# AST1080 register map
File version: 1.0
CPU: CM4 r0p1, little endian, MPU, FPU, 4 interrupt priority bits, 256 interrupts
Registers are 32-bit, read-write, reset 0x0 unless marked. A register's access mark holds for its fields unless they carry their own. Offsets are from the block's base; [hi:lo] are bit positions; {n}, {i} and the like mark numbered series.

## pric_io (part 2 of 3)
Base 0x74100000
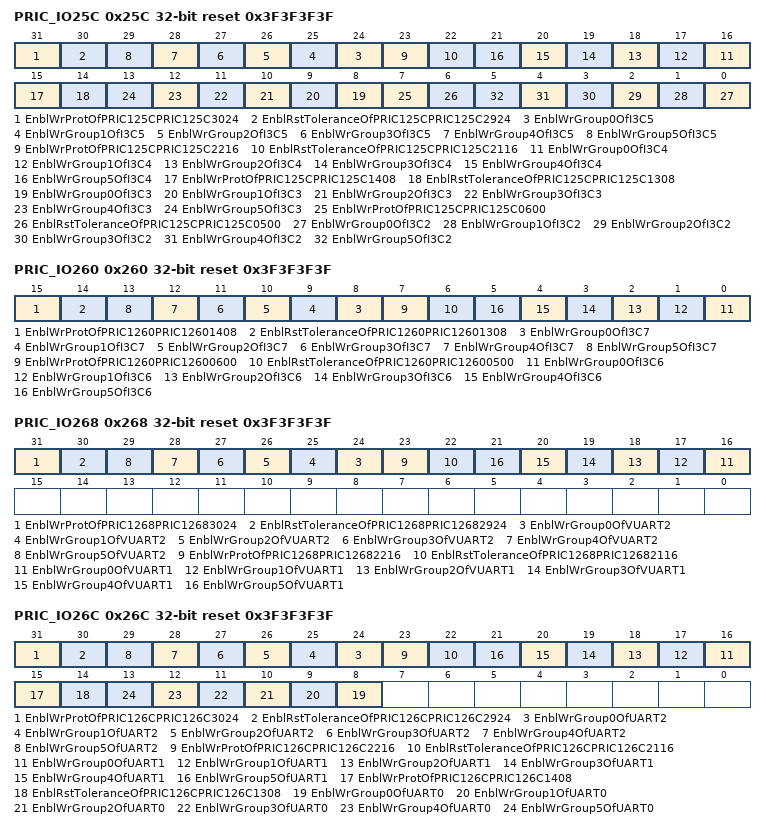
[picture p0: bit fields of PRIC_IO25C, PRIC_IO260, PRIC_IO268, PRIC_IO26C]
0x25C PRIC_IO25C reset 0x3F3F3F3F — Slave Write Group Setting Register \#23
  [31] EnblWrProtOfPRIC125CPRIC125C3024 — Enable Write Protection of PRIC125CPRIC1_25C[30:24]
  [30] EnblRstToleranceOfPRIC125CPRIC125C2924 — Enable Reset Tolerance of PRIC125CPRIC1_25C[29:24]
    0=Reset_By_SRST; 1=Reset_By_SRST_And_PSP_Reset
  [n+24] EnblWrGroup{n}OfI3C5 (n=0..5) — Enable Write Group #{n} of I3C5
  [23] EnblWrProtOfPRIC125CPRIC125C2216 — Enable Write Protection of PRIC125CPRIC1_25C[22:16]
  [22] EnblRstToleranceOfPRIC125CPRIC125C2116 — Enable Reset Tolerance of PRIC125CPRIC1_25C[21:16]
    0=Reset_By_SRST; 1=Reset_By_SRST_And_PSP_Reset
  [n+16] EnblWrGroup{n}OfI3C4 (n=0..5) — Enable Write Group #{n} of I3C4
  [15] EnblWrProtOfPRIC125CPRIC125C1408 — Enable Write Protection of PRIC125CPRIC1_25C[14:08]
  [14] EnblRstToleranceOfPRIC125CPRIC125C1308 — Enable Reset Tolerance of PRIC125CPRIC1_25C[13:08]
    0=Reset_By_SRST; 1=Reset_By_SRST_And_PSP_Reset
  [n+8] EnblWrGroup{n}OfI3C3 (n=0..5) — Enable Write Group #{n} of I3C3
  [7] EnblWrProtOfPRIC125CPRIC125C0600 — Enable Write Protection of PRIC125CPRIC1_25C[06:00]
  [6] EnblRstToleranceOfPRIC125CPRIC125C0500 — Enable Reset Tolerance of PRIC125CPRIC1_25C[05:00]
    0=Reset_By_SRST; 1=Reset_By_SRST_And_PSP_Reset
  [n] EnblWrGroup{n}OfI3C2 (n=0..5) — Enable Write Group #{n} of I3C2
0x260 PRIC_IO260 reset 0x3F3F3F3F — Slave Write Group Setting Register \#24
  [15] EnblWrProtOfPRIC1260PRIC12601408 — Enable Write Protection of PRIC1260PRIC1_260[14:08]
  [14] EnblRstToleranceOfPRIC1260PRIC12601308 — Enable Reset Tolerance of PRIC1260PRIC1_260[13:08]
    0=Reset_By_SRST; 1=Reset_By_SRST_And_PSP_Reset
  [n+8] EnblWrGroup{n}OfI3C7 (n=0..5) — Enable Write Group #{n} of I3C7
  [7] EnblWrProtOfPRIC1260PRIC12600600 — Enable Write Protection of PRIC1260PRIC1_260[06:00]
  [6] EnblRstToleranceOfPRIC1260PRIC12600500 — Enable Reset Tolerance of PRIC1260PRIC1_260[05:00]
    0=Reset_By_SRST; 1=Reset_By_SRST_And_PSP_Reset
  [n] EnblWrGroup{n}OfI3C6 (n=0..5) — Enable Write Group #{n} of I3C6
0x264 PRIC_IO264 reset 0x3F3F3F3F (reset mask 0x0) — Slave Write Group Setting Register \#25
0x268 PRIC_IO268 reset 0x3F3F3F3F — Slave Write Group Setting Register \#26
  [31] EnblWrProtOfPRIC1268PRIC12683024 — Enable Write Protection of PRIC1268PRIC1_268[30:24]
  [30] EnblRstToleranceOfPRIC1268PRIC12682924 — Enable Reset Tolerance of PRIC1268PRIC1_268[29:24]
    0=Reset_By_SRST; 1=Reset_By_SRST_And_PSP_Reset
  [n+24] EnblWrGroup{n}OfVUART2 (n=0..5) — Enable Write Group #{n} of VUART2
  [23] EnblWrProtOfPRIC1268PRIC12682216 — Enable Write Protection of PRIC1268PRIC1_268[22:16]
  [22] EnblRstToleranceOfPRIC1268PRIC12682116 — Enable Reset Tolerance of PRIC1268PRIC1_268[21:16]
    0=Reset_By_SRST; 1=Reset_By_SRST_And_PSP_Reset
  [n+16] EnblWrGroup{n}OfVUART1 (n=0..5) — Enable Write Group #{n} of VUART1
0x26C PRIC_IO26C reset 0x3F3F3F3F — Slave Write Group Setting Register \#27
  [31] EnblWrProtOfPRIC126CPRIC126C3024 — Enable Write Protection of PRIC126CPRIC1_26C[30:24]
  [30] EnblRstToleranceOfPRIC126CPRIC126C2924 — Enable Reset Tolerance of PRIC126CPRIC1_26C[29:24]
    0=Reset_By_SRST; 1=Reset_By_SRST_And_PSP_Reset
  [n+24] EnblWrGroup{n}OfUART2 (n=0..5) — Enable Write Group #{n} of UART2
  [23] EnblWrProtOfPRIC126CPRIC126C2216 — Enable Write Protection of PRIC126CPRIC1_26C[22:16]
  [22] EnblRstToleranceOfPRIC126CPRIC126C2116 — Enable Reset Tolerance of PRIC126CPRIC1_26C[21:16]
    0=Reset_By_SRST; 1=Reset_By_SRST_And_PSP_Reset
  [n+16] EnblWrGroup{n}OfUART1 (n=0..5) — Enable Write Group #{n} of UART1
  [15] EnblWrProtOfPRIC126CPRIC126C1408 — Enable Write Protection of PRIC126CPRIC1_26C[14:08]
  [14] EnblRstToleranceOfPRIC126CPRIC126C1308 — Enable Reset Tolerance of PRIC126CPRIC1_26C[13:08]
    0=Reset_By_SRST; 1=Reset_By_SRST_And_PSP_Reset
  [n+8] EnblWrGroup{n}OfUART0 (n=0..5) — Enable Write Group #{n} of UART0
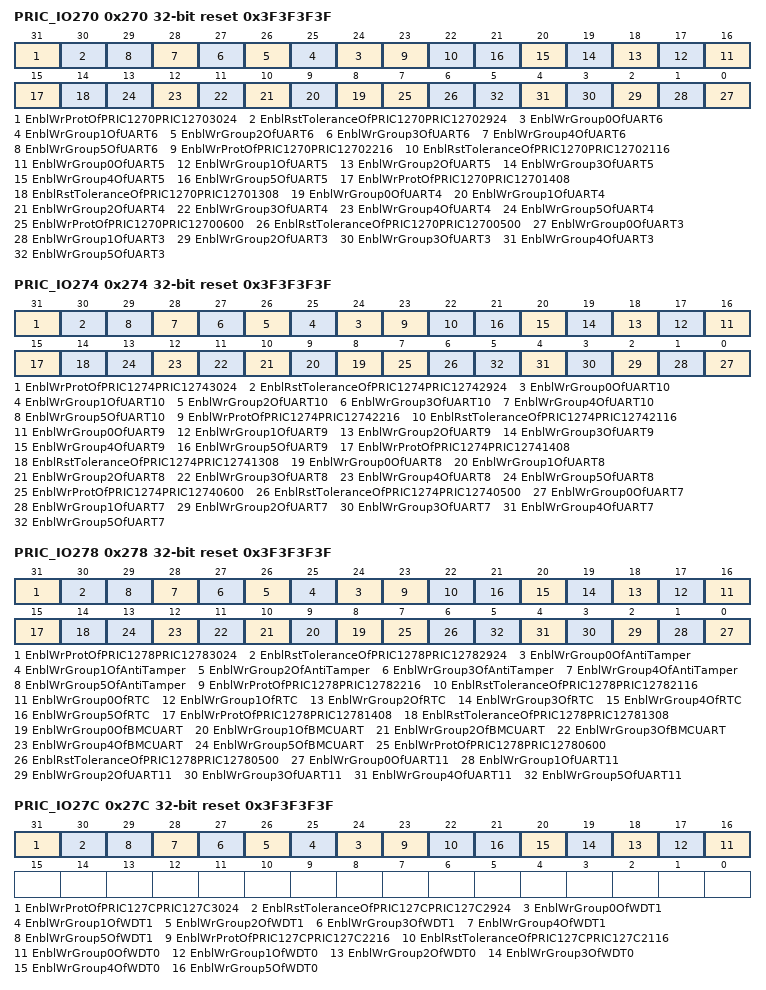
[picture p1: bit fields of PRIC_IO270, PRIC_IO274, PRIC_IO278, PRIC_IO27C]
0x270 PRIC_IO270 reset 0x3F3F3F3F — Slave Write Group Setting Register \#28
  [31] EnblWrProtOfPRIC1270PRIC12703024 — Enable Write Protection of PRIC1270PRIC1_270[30:24]
  [30] EnblRstToleranceOfPRIC1270PRIC12702924 — Enable Reset Tolerance of PRIC1270PRIC1_270[29:24]
    0=Reset_By_SRST; 1=Reset_By_SRST_And_PSP_Reset
  [n+24] EnblWrGroup{n}OfUART6 (n=0..5) — Enable Write Group #{n} of UART6
  [23] EnblWrProtOfPRIC1270PRIC12702216 — Enable Write Protection of PRIC1270PRIC1_270[22:16]
  [22] EnblRstToleranceOfPRIC1270PRIC12702116 — Enable Reset Tolerance of PRIC1270PRIC1_270[21:16]
    0=Reset_By_SRST; 1=Reset_By_SRST_And_PSP_Reset
  [n+16] EnblWrGroup{n}OfUART5 (n=0..5) — Enable Write Group #{n} of UART5
  [15] EnblWrProtOfPRIC1270PRIC12701408 — Enable Write Protection of PRIC1270PRIC1_270[14:08]
  [14] EnblRstToleranceOfPRIC1270PRIC12701308 — Enable Reset Tolerance of PRIC1270PRIC1_270[13:08]
    0=Reset_By_SRST; 1=Reset_By_SRST_And_PSP_Reset
  [n+8] EnblWrGroup{n}OfUART4 (n=0..5) — Enable Write Group #{n} of UART4
  [7] EnblWrProtOfPRIC1270PRIC12700600 — Enable Write Protection of PRIC1270PRIC1_270[06:00]
  [6] EnblRstToleranceOfPRIC1270PRIC12700500 — Enable Reset Tolerance of PRIC1270PRIC1_270[05:00]
    0=Reset_By_SRST; 1=Reset_By_SRST_And_PSP_Reset
  [n] EnblWrGroup{n}OfUART3 (n=0..5) — Enable Write Group #{n} of UART3
0x274 PRIC_IO274 reset 0x3F3F3F3F — Slave Write Group Setting Register \#29
  [31] EnblWrProtOfPRIC1274PRIC12743024 — Enable Write Protection of PRIC1274PRIC1_274[30:24]
  [30] EnblRstToleranceOfPRIC1274PRIC12742924 — Enable Reset Tolerance of PRIC1274PRIC1_274[29:24]
    0=Reset_By_SRST; 1=Reset_By_SRST_And_PSP_Reset
  [n+24] EnblWrGroup{n}OfUART10 (n=0..5) — Enable Write Group #{n} of UART10
  [23] EnblWrProtOfPRIC1274PRIC12742216 — Enable Write Protection of PRIC1274PRIC1_274[22:16]
  [22] EnblRstToleranceOfPRIC1274PRIC12742116 — Enable Reset Tolerance of PRIC1274PRIC1_274[21:16]
    0=Reset_By_SRST; 1=Reset_By_SRST_And_PSP_Reset
  [n+16] EnblWrGroup{n}OfUART9 (n=0..5) — Enable Write Group #{n} of UART9
  [15] EnblWrProtOfPRIC1274PRIC12741408 — Enable Write Protection of PRIC1274PRIC1_274[14:08]
  [14] EnblRstToleranceOfPRIC1274PRIC12741308 — Enable Reset Tolerance of PRIC1274PRIC1_274[13:08]
    0=Reset_By_SRST; 1=Reset_By_SRST_And_PSP_Reset
  [n+8] EnblWrGroup{n}OfUART8 (n=0..5) — Enable Write Group #{n} of UART8
  [7] EnblWrProtOfPRIC1274PRIC12740600 — Enable Write Protection of PRIC1274PRIC1_274[06:00]
  [6] EnblRstToleranceOfPRIC1274PRIC12740500 — Enable Reset Tolerance of PRIC1274PRIC1_274[05:00]
    0=Reset_By_SRST; 1=Reset_By_SRST_And_PSP_Reset
  [n] EnblWrGroup{n}OfUART7 (n=0..5) — Enable Write Group #{n} of UART7
0x278 PRIC_IO278 reset 0x3F3F3F3F — Slave Write Group Setting Register \#30
  [31] EnblWrProtOfPRIC1278PRIC12783024 — Enable Write Protection of PRIC1278PRIC1_278[30:24]
  [30] EnblRstToleranceOfPRIC1278PRIC12782924 — Enable Reset Tolerance of PRIC1278PRIC1_278[29:24]
    0=Reset_By_SRST; 1=Reset_By_SRST_And_PSP_Reset
  [n+24] EnblWrGroup{n}OfAntiTamper (n=0..5) — Enable Write Group #{n} of Anti Tamper
  [23] EnblWrProtOfPRIC1278PRIC12782216 — Enable Write Protection of PRIC1278PRIC1_278[22:16]
  [22] EnblRstToleranceOfPRIC1278PRIC12782116 — Enable Reset Tolerance of PRIC1278PRIC1_278[21:16]
    0=Reset_By_SRST; 1=Reset_By_SRST_And_PSP_Reset
  [n+16] EnblWrGroup{n}OfRTC (n=0..5) — Enable Write Group #{n} of RTC
  [15] EnblWrProtOfPRIC1278PRIC12781408 — Enable Write Protection of PRIC1278PRIC1_278[14:08]
  [14] EnblRstToleranceOfPRIC1278PRIC12781308 — Enable Reset Tolerance of PRIC1278PRIC1_278[13:08]
    0=Reset_By_SRST; 1=Reset_By_SRST_And_PSP_Reset
  [n+8] EnblWrGroup{n}OfBMCUART (n=0..5) — Enable Write Group #{n} of BMC UART
  [7] EnblWrProtOfPRIC1278PRIC12780600 — Enable Write Protection of PRIC1278PRIC1_278[06:00]
  [6] EnblRstToleranceOfPRIC1278PRIC12780500 — Enable Reset Tolerance of PRIC1278PRIC1_278[05:00]
    0=Reset_By_SRST; 1=Reset_By_SRST_And_PSP_Reset
  [n] EnblWrGroup{n}OfUART11 (n=0..5) — Enable Write Group #{n} of UART11
0x27C PRIC_IO27C reset 0x3F3F3F3F — Slave Write Group Setting Register \#31
  [31] EnblWrProtOfPRIC127CPRIC127C3024 — Enable Write Protection of PRIC127CPRIC1_27C[30:24]
  [30] EnblRstToleranceOfPRIC127CPRIC127C2924 — Enable Reset Tolerance of PRIC127CPRIC1_27C[29:24]
    0=Reset_By_SRST; 1=Reset_By_SRST_And_PSP_Reset
  [n+24] EnblWrGroup{n}OfWDT1 (n=0..5) — Enable Write Group #{n} of WDT 1
  [23] EnblWrProtOfPRIC127CPRIC127C2216 — Enable Write Protection of PRIC127CPRIC1_27C[22:16]
  [22] EnblRstToleranceOfPRIC127CPRIC127C2116 — Enable Reset Tolerance of PRIC127CPRIC1_27C[21:16]
    0=Reset_By_SRST; 1=Reset_By_SRST_And_PSP_Reset
  [n+16] EnblWrGroup{n}OfWDT0 (n=0..5) — Enable Write Group #{n} of WDT 0
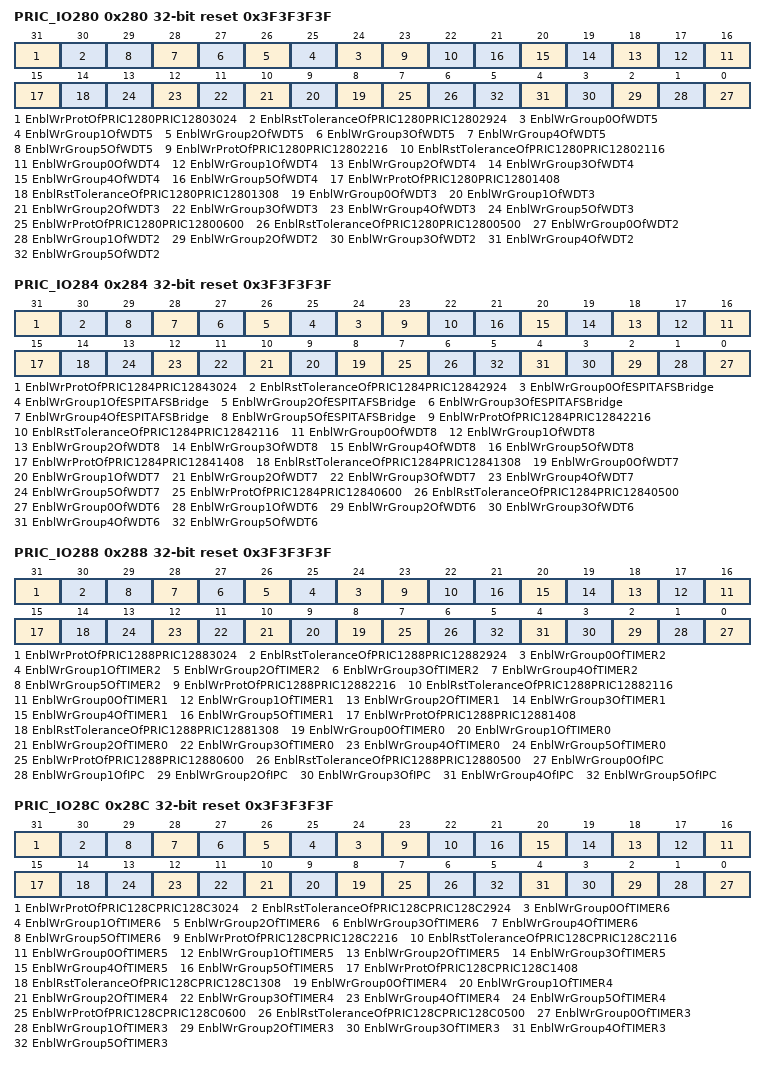
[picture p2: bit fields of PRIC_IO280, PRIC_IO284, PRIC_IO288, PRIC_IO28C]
0x280 PRIC_IO280 reset 0x3F3F3F3F — Slave Write Group Setting Register \#32
  [31] EnblWrProtOfPRIC1280PRIC12803024 — Enable Write Protection of PRIC1280PRIC1_280[30:24]
  [30] EnblRstToleranceOfPRIC1280PRIC12802924 — Enable Reset Tolerance of PRIC1280PRIC1_280[29:24]
    0=Reset_By_SRST; 1=Reset_By_SRST_And_PSP_Reset
  [n+24] EnblWrGroup{n}OfWDT5 (n=0..5) — Enable Write Group #{n} of WDT 5
  [23] EnblWrProtOfPRIC1280PRIC12802216 — Enable Write Protection of PRIC1280PRIC1_280[22:16]
  [22] EnblRstToleranceOfPRIC1280PRIC12802116 — Enable Reset Tolerance of PRIC1280PRIC1_280[21:16]
    0=Reset_By_SRST; 1=Reset_By_SRST_And_PSP_Reset
  [n+16] EnblWrGroup{n}OfWDT4 (n=0..5) — Enable Write Group #{n} of WDT 4
  [15] EnblWrProtOfPRIC1280PRIC12801408 — Enable Write Protection of PRIC1280PRIC1_280[14:08]
  [14] EnblRstToleranceOfPRIC1280PRIC12801308 — Enable Reset Tolerance of PRIC1280PRIC1_280[13:08]
    0=Reset_By_SRST; 1=Reset_By_SRST_And_PSP_Reset
  [n+8] EnblWrGroup{n}OfWDT3 (n=0..5) — Enable Write Group #{n} of WDT 3
  [7] EnblWrProtOfPRIC1280PRIC12800600 — Enable Write Protection of PRIC1280PRIC1_280[06:00]
  [6] EnblRstToleranceOfPRIC1280PRIC12800500 — Enable Reset Tolerance of PRIC1280PRIC1_280[05:00]
    0=Reset_By_SRST; 1=Reset_By_SRST_And_PSP_Reset
  [n] EnblWrGroup{n}OfWDT2 (n=0..5) — Enable Write Group #{n} of WDT 2
0x284 PRIC_IO284 reset 0x3F3F3F3F — Slave Write Group Setting Register \#33
  [31] EnblWrProtOfPRIC1284PRIC12843024 — Enable Write Protection of PRIC1284PRIC1_284[30:24]
  [30] EnblRstToleranceOfPRIC1284PRIC12842924 — Enable Reset Tolerance of PRIC1284PRIC1_284[29:24]
    0=Reset_By_SRST; 1=Reset_By_SRST_And_PSP_Reset
  [n+24] EnblWrGroup{n}OfESPITAFSBridge (n=0..5) — Enable Write Group #{n} of eSPI TAFS Bridge
  [23] EnblWrProtOfPRIC1284PRIC12842216 — Enable Write Protection of PRIC1284PRIC1_284[22:16]
  [22] EnblRstToleranceOfPRIC1284PRIC12842116 — Enable Reset Tolerance of PRIC1284PRIC1_284[21:16]
    0=Reset_By_SRST; 1=Reset_By_SRST_And_PSP_Reset
  [n+16] EnblWrGroup{n}OfWDT8 (n=0..5) — Enable Write Group #{n} of WDT 8
  [15] EnblWrProtOfPRIC1284PRIC12841408 — Enable Write Protection of PRIC1284PRIC1_284[14:08]
  [14] EnblRstToleranceOfPRIC1284PRIC12841308 — Enable Reset Tolerance of PRIC1284PRIC1_284[13:08]
    0=Reset_By_SRST; 1=Reset_By_SRST_And_PSP_Reset
  [n+8] EnblWrGroup{n}OfWDT7 (n=0..5) — Enable Write Group #{n} of WDT 7
  [7] EnblWrProtOfPRIC1284PRIC12840600 — Enable Write Protection of PRIC1284PRIC1_284[06:00]
  [6] EnblRstToleranceOfPRIC1284PRIC12840500 — Enable Reset Tolerance of PRIC1284PRIC1_284[05:00]
    0=Reset_By_SRST; 1=Reset_By_SRST_And_PSP_Reset
  [n] EnblWrGroup{n}OfWDT6 (n=0..5) — Enable Write Group #{n} of WDT 6
0x288 PRIC_IO288 reset 0x3F3F3F3F — Slave Write Group Setting Register \#34
  [31] EnblWrProtOfPRIC1288PRIC12883024 — Enable Write Protection of PRIC1288PRIC1_288[30:24]
  [30] EnblRstToleranceOfPRIC1288PRIC12882924 — Enable Reset Tolerance of PRIC1288PRIC1_288[29:24]
    0=Reset_By_SRST; 1=Reset_By_SRST_And_PSP_Reset
  [n+24] EnblWrGroup{n}OfTIMER2 (n=0..5) — Enable Write Group #{n} of TIMER2
  [23] EnblWrProtOfPRIC1288PRIC12882216 — Enable Write Protection of PRIC1288PRIC1_288[22:16]
  [22] EnblRstToleranceOfPRIC1288PRIC12882116 — Enable Reset Tolerance of PRIC1288PRIC1_288[21:16]
    0=Reset_By_SRST; 1=Reset_By_SRST_And_PSP_Reset
  [n+16] EnblWrGroup{n}OfTIMER1 (n=0..5) — Enable Write Group #{n} of TIMER1
  [15] EnblWrProtOfPRIC1288PRIC12881408 — Enable Write Protection of PRIC1288PRIC1_288[14:08]
  [14] EnblRstToleranceOfPRIC1288PRIC12881308 — Enable Reset Tolerance of PRIC1288PRIC1_288[13:08]
    0=Reset_By_SRST; 1=Reset_By_SRST_And_PSP_Reset
  [n+8] EnblWrGroup{n}OfTIMER0 (n=0..5) — Enable Write Group #{n} of TIMER0
  [7] EnblWrProtOfPRIC1288PRIC12880600 — Enable Write Protection of PRIC1288PRIC1_288[06:00]
  [6] EnblRstToleranceOfPRIC1288PRIC12880500 — Enable Reset Tolerance of PRIC1288PRIC1_288[05:00]
    0=Reset_By_SRST; 1=Reset_By_SRST_And_PSP_Reset
  [n] EnblWrGroup{n}OfIPC (n=0..5) — Enable Write Group #{n} of IPC
0x28C PRIC_IO28C reset 0x3F3F3F3F — Slave Write Group Setting Register \#35
  [31] EnblWrProtOfPRIC128CPRIC128C3024 — Enable Write Protection of PRIC128CPRIC1_28C[30:24]
  [30] EnblRstToleranceOfPRIC128CPRIC128C2924 — Enable Reset Tolerance of PRIC128CPRIC1_28C[29:24]
    0=Reset_By_SRST; 1=Reset_By_SRST_And_PSP_Reset
  [n+24] EnblWrGroup{n}OfTIMER6 (n=0..5) — Enable Write Group #{n} of TIMER6
  [23] EnblWrProtOfPRIC128CPRIC128C2216 — Enable Write Protection of PRIC128CPRIC1_28C[22:16]
  [22] EnblRstToleranceOfPRIC128CPRIC128C2116 — Enable Reset Tolerance of PRIC128CPRIC1_28C[21:16]
    0=Reset_By_SRST; 1=Reset_By_SRST_And_PSP_Reset
  [n+16] EnblWrGroup{n}OfTIMER5 (n=0..5) — Enable Write Group #{n} of TIMER5
  [15] EnblWrProtOfPRIC128CPRIC128C1408 — Enable Write Protection of PRIC128CPRIC1_28C[14:08]
  [14] EnblRstToleranceOfPRIC128CPRIC128C1308 — Enable Reset Tolerance of PRIC128CPRIC1_28C[13:08]
    0=Reset_By_SRST; 1=Reset_By_SRST_And_PSP_Reset
  [n+8] EnblWrGroup{n}OfTIMER4 (n=0..5) — Enable Write Group #{n} of TIMER4
  [7] EnblWrProtOfPRIC128CPRIC128C0600 — Enable Write Protection of PRIC128CPRIC1_28C[06:00]
  [6] EnblRstToleranceOfPRIC128CPRIC128C0500 — Enable Reset Tolerance of PRIC128CPRIC1_28C[05:00]
    0=Reset_By_SRST; 1=Reset_By_SRST_And_PSP_Reset
  [n] EnblWrGroup{n}OfTIMER3 (n=0..5) — Enable Write Group #{n} of TIMER3
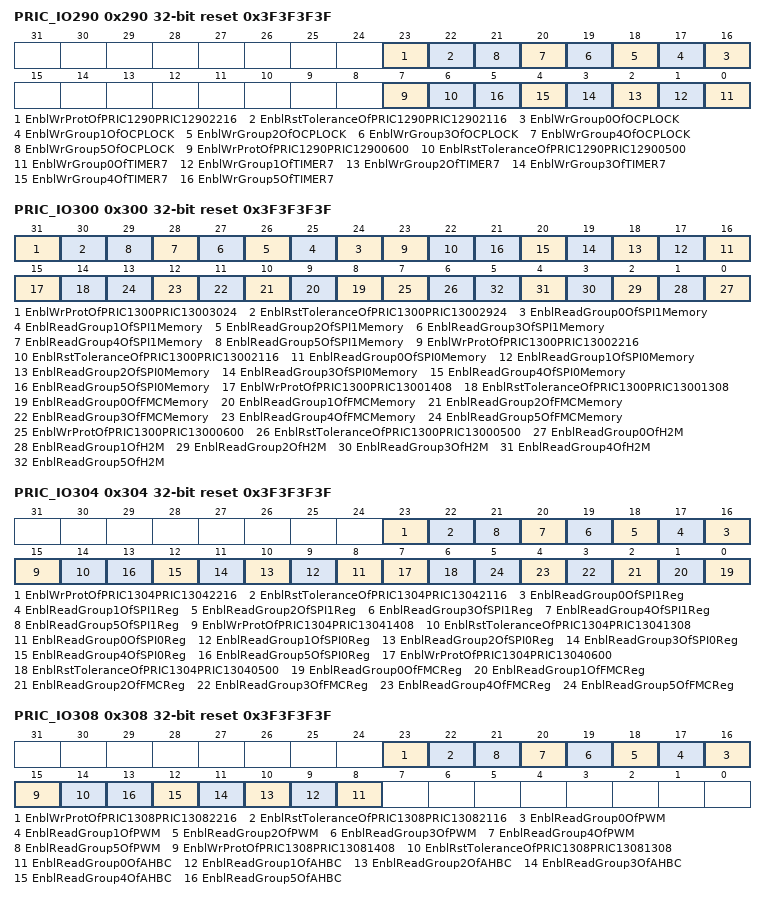
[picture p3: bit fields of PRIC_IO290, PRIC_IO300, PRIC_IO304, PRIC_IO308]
0x290 PRIC_IO290 reset 0x3F3F3F3F — Slave Write Group Setting Register \#36
  [23] EnblWrProtOfPRIC1290PRIC12902216 — Enable Write Protection of PRIC1290PRIC1_290[22:16]
  [22] EnblRstToleranceOfPRIC1290PRIC12902116 — Enable Reset Tolerance of PRIC1290PRIC1_290[21:16]
    0=Reset_By_SRST; 1=Reset_By_SRST_And_PSP_Reset
  [n+16] EnblWrGroup{n}OfOCPLOCK (n=0..5) — Enable Write Group #{n} of OCP_LOCK
  [7] EnblWrProtOfPRIC1290PRIC12900600 — Enable Write Protection of PRIC1290PRIC1_290[06:00]
  [6] EnblRstToleranceOfPRIC1290PRIC12900500 — Enable Reset Tolerance of PRIC1290PRIC1_290[05:00]
    0=Reset_By_SRST; 1=Reset_By_SRST_And_PSP_Reset
  [n] EnblWrGroup{n}OfTIMER7 (n=0..5) — Enable Write Group #{n} of TIMER7
0x294 PRIC_IO294 reset 0x3F3F3F3F (reset mask 0x0) — Slave Write Group Setting Register \#37
0x298 PRIC_IO298 reset 0x3F3F3F3F (reset mask 0x0) — Slave Write Group Setting Register \#38
0x29C PRIC_IO29C reset 0x3F3F3F3F (reset mask 0x0) — Slave Write Group Setting Register \#39
0x2A0 PRIC_IO2A0 reset 0x3F3F3F3F (reset mask 0x0) — Slave Write Group Setting Register \#40
0x2A4 PRIC_IO2A4 reset 0x3F3F3F3F (reset mask 0x0) — Slave Write Group Setting Register \#41
0x2A8 PRIC_IO2A8 reset 0x3F3F3F3F (reset mask 0x0) — Slave Write Group Setting Register \#42
0x2AC PRIC_IO2AC reset 0x3F3F3F3F (reset mask 0x0) — Slave Write Group Setting Register \#43
0x2B0 PRIC_IO2B0 reset 0x3F3F3F3F (reset mask 0x0) — Slave Write Group Setting Register \#44
0x2B4 PRIC_IO2B4 reset 0x3F3F3F3F (reset mask 0x0) — Slave Write Group Setting Register \#45
0x2B8 PRIC_IO2B8 reset 0x3F3F3F3F (reset mask 0x0) — Slave Write Group Setting Register \#46
0x2BC PRIC_IO2BC reset 0x3F3F3F3F (reset mask 0x0) — Slave Write Group Setting Register \#47
0x2C0 PRIC_IO2C0 reset 0x3F3F3F3F (reset mask 0x0) — Slave Write Group Setting Register \#48
0x2C4 PRIC_IO2C4 reset 0x3F3F3F3F (reset mask 0x0) — Slave Write Group Setting Register \#49
0x2C8 PRIC_IO2C8 reset 0x3F3F3F3F (reset mask 0x0) — Slave Write Group Setting Register \#50
0x2CC PRIC_IO2CC reset 0x3F3F3F3F (reset mask 0x0) — Slave Write Group Setting Register \#51
0x2D0 PRIC_IO2D0 reset 0x3F3F3F3F (reset mask 0x0) — Slave Write Group Setting Register \#52
0x2D4 PRIC_IO2D4 reset 0x3F3F3F3F (reset mask 0x0) — Slave Write Group Setting Register \#53
0x2D8 PRIC_IO2D8 reset 0x3F3F3F3F (reset mask 0x0) — Slave Write Group Setting Register \#54
0x2DC PRIC_IO2DC reset 0x3F3F3F3F (reset mask 0x0) — Slave Write Group Setting Register \#55
0x2E0 PRIC_IO2E0 reset 0x3F3F3F3F (reset mask 0x0) — Slave Write Group Setting Register \#56
0x2E4 PRIC_IO2E4 reset 0x3F3F3F3F (reset mask 0x0) — Slave Write Group Setting Register \#57
0x2E8 PRIC_IO2E8 reset 0x3F3F3F3F (reset mask 0x0) — Slave Write Group Setting Register \#58
0x2EC PRIC_IO2EC reset 0x3F3F3F3F (reset mask 0x0) — Slave Write Group Setting Register \#59
0x2F0 PRIC_IO2F0 reset 0x3F3F3F3F (reset mask 0x0) — Slave Write Group Setting Register \#60
0x2F4 PRIC_IO2F4 reset 0x3F3F3F3F (reset mask 0x0) — Slave Write Group Setting Register \#61
0x2F8 PRIC_IO2F8 reset 0x3F3F3F3F (reset mask 0x0) — Slave Write Group Setting Register \#62
0x2FC PRIC_IO2FC reset 0x3F3F3F3F (reset mask 0x0) — Slave Write Group Setting Register \#63
0x300 PRIC_IO300 reset 0x3F3F3F3F — Slave Read Group Setting Register \#0
  [31] EnblWrProtOfPRIC1300PRIC13003024 — Enable Write Protection of PRIC1300PRIC1_300[30:24]
  [30] EnblRstToleranceOfPRIC1300PRIC13002924 — Enable Reset Tolerance of PRIC1300PRIC1_300[29:24]
    0=Reset_By_SRST; 1=Reset_By_SRST_And_PSP_Reset
  [n+24] EnblReadGroup{n}OfSPI1Memory (n=0..5) — Enable Read Group #{n} of SPI1 Memory
  [23] EnblWrProtOfPRIC1300PRIC13002216 — Enable Write Protection of PRIC1300PRIC1_300[22:16]
  [22] EnblRstToleranceOfPRIC1300PRIC13002116 — Enable Reset Tolerance of PRIC1300PRIC1_300[21:16]
    0=Reset_By_SRST; 1=Reset_By_SRST_And_PSP_Reset
  [n+16] EnblReadGroup{n}OfSPI0Memory (n=0..5) — Enable Read Group #{n} of SPI0 Memory
  [15] EnblWrProtOfPRIC1300PRIC13001408 — Enable Write Protection of PRIC1300PRIC1_300[14:08]
  [14] EnblRstToleranceOfPRIC1300PRIC13001308 — Enable Reset Tolerance of PRIC1300PRIC1_300[13:08]
    0=Reset_By_SRST; 1=Reset_By_SRST_And_PSP_Reset
  [n+8] EnblReadGroup{n}OfFMCMemory (n=0..5) — Enable Read Group #{n} of FMC Memory
  [7] EnblWrProtOfPRIC1300PRIC13000600 — Enable Write Protection of PRIC1300PRIC1_300[06:00]
  [6] EnblRstToleranceOfPRIC1300PRIC13000500 — Enable Reset Tolerance of PRIC1300PRIC1_300[05:00]
    0=Reset_By_SRST; 1=Reset_By_SRST_And_PSP_Reset
  [n] EnblReadGroup{n}OfH2M (n=0..5) — Enable Read Group #{n} of H2M
0x304 PRIC_IO304 reset 0x3F3F3F3F — Slave Read Group Setting Register \#1
  [23] EnblWrProtOfPRIC1304PRIC13042216 — Enable Write Protection of PRIC1304PRIC1_304[22:16]
  [22] EnblRstToleranceOfPRIC1304PRIC13042116 — Enable Reset Tolerance of PRIC1304PRIC1_304[21:16]
    0=Reset_By_SRST; 1=Reset_By_SRST_And_PSP_Reset
  [n+16] EnblReadGroup{n}OfSPI1Reg (n=0..5) — Enable Read Group #{n} of SPI1 Register
  [15] EnblWrProtOfPRIC1304PRIC13041408 — Enable Write Protection of PRIC1304PRIC1_304[14:08]
  [14] EnblRstToleranceOfPRIC1304PRIC13041308 — Enable Reset Tolerance of PRIC1304PRIC1_304[13:08]
    0=Reset_By_SRST; 1=Reset_By_SRST_And_PSP_Reset
  [n+8] EnblReadGroup{n}OfSPI0Reg (n=0..5) — Enable Read Group #{n} of SPI0 Register
  [7] EnblWrProtOfPRIC1304PRIC13040600 — Enable Write Protection of PRIC1304PRIC1_304[06:00]
  [6] EnblRstToleranceOfPRIC1304PRIC13040500 — Enable Reset Tolerance of PRIC1304PRIC1_304[05:00]
    0=Reset_By_SRST; 1=Reset_By_SRST_And_PSP_Reset
  [n] EnblReadGroup{n}OfFMCReg (n=0..5) — Enable Read Group #{n} of FMC Register
0x308 PRIC_IO308 reset 0x3F3F3F3F — Slave Read Group Setting Register \#2
  [23] EnblWrProtOfPRIC1308PRIC13082216 — Enable Write Protection of PRIC1308PRIC1_308[22:16]
  [22] EnblRstToleranceOfPRIC1308PRIC13082116 — Enable Reset Tolerance of PRIC1308PRIC1_308[21:16]
    0=Reset_By_SRST; 1=Reset_By_SRST_And_PSP_Reset
  [n+16] EnblReadGroup{n}OfPWM (n=0..5) — Enable Read Group #{n} of PWM
  [15] EnblWrProtOfPRIC1308PRIC13081408 — Enable Write Protection of PRIC1308PRIC1_308[14:08]
  [14] EnblRstToleranceOfPRIC1308PRIC13081308 — Enable Reset Tolerance of PRIC1308PRIC1_308[13:08]
    0=Reset_By_SRST; 1=Reset_By_SRST_And_PSP_Reset
  [n+8] EnblReadGroup{n}OfAHBC (n=0..5) — Enable Read Group #{n} of AHBC
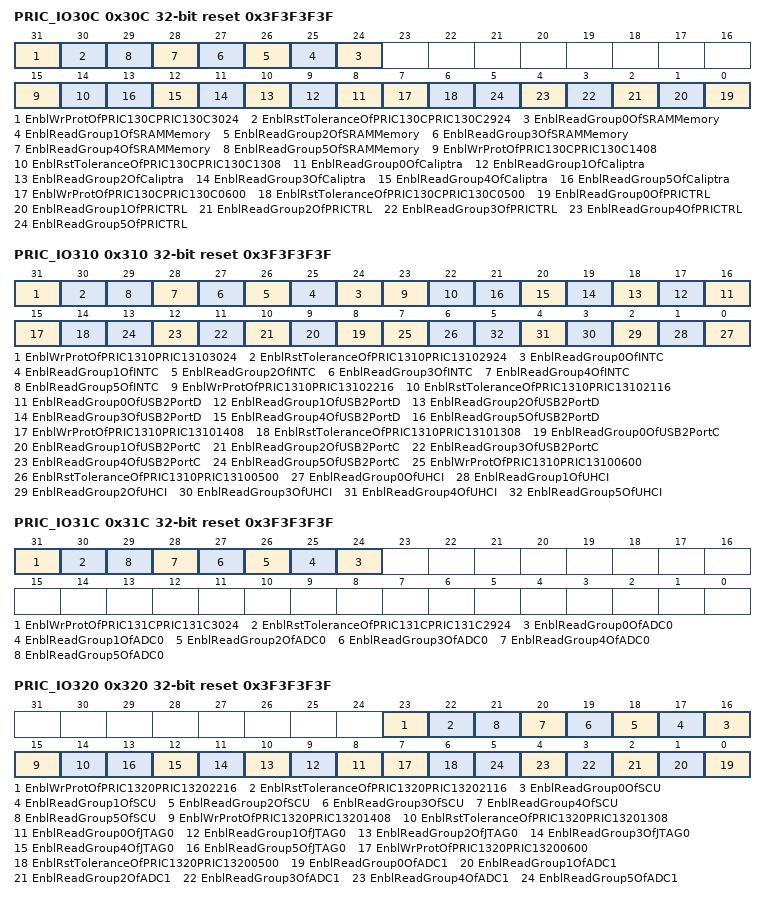
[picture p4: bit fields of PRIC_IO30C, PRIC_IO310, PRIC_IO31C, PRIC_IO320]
0x30C PRIC_IO30C reset 0x3F3F3F3F — Slave Read Group Setting Register \#3
  [31] EnblWrProtOfPRIC130CPRIC130C3024 — Enable Write Protection of PRIC130CPRIC1_30C[30:24]
  [30] EnblRstToleranceOfPRIC130CPRIC130C2924 — Enable Reset Tolerance of PRIC130CPRIC1_30C[29:24]
    0=Reset_By_SRST; 1=Reset_By_SRST_And_PSP_Reset
  [n+24] EnblReadGroup{n}OfSRAMMemory (n=0..5) — Enable Read Group #{n} of SRAM Memory
  [15] EnblWrProtOfPRIC130CPRIC130C1408 — Enable Write Protection of PRIC130CPRIC1_30C[14:08]
  [14] EnblRstToleranceOfPRIC130CPRIC130C1308 — Enable Reset Tolerance of PRIC130CPRIC1_30C[13:08]
    0=Reset_By_SRST; 1=Reset_By_SRST_And_PSP_Reset
  [n+8] EnblReadGroup{n}OfCaliptra (n=0..5) — Enable Read Group #{n} of Caliptra
  [7] EnblWrProtOfPRIC130CPRIC130C0600 — Enable Write Protection of PRIC130CPRIC1_30C[06:00]
  [6] EnblRstToleranceOfPRIC130CPRIC130C0500 — Enable Reset Tolerance of PRIC130CPRIC1_30C[05:00]
    0=Reset_By_SRST; 1=Reset_By_SRST_And_PSP_Reset
  [n] EnblReadGroup{n}OfPRICTRL (n=0..5) — Enable Read Group #{n} of PRICTRL
0x310 PRIC_IO310 reset 0x3F3F3F3F — Slave Read Group Setting Register \#4
  [31] EnblWrProtOfPRIC1310PRIC13103024 — Enable Write Protection of PRIC1310PRIC1_310[30:24]
  [30] EnblRstToleranceOfPRIC1310PRIC13102924 — Enable Reset Tolerance of PRIC1310PRIC1_310[29:24]
    0=Reset_By_SRST; 1=Reset_By_SRST_And_PSP_Reset
  [n+24] EnblReadGroup{n}OfINTC (n=0..5) — Enable Read Group #{n} of INTC
  [23] EnblWrProtOfPRIC1310PRIC13102216 — Enable Write Protection of PRIC1310PRIC1_310[22:16]
  [22] EnblRstToleranceOfPRIC1310PRIC13102116 — Enable Reset Tolerance of PRIC1310PRIC1_310[21:16]
    0=Reset_By_SRST; 1=Reset_By_SRST_And_PSP_Reset
  [n+16] EnblReadGroup{n}OfUSB2PortD (n=0..5) — Enable Read Group #{n} of USB2 Port D
  [15] EnblWrProtOfPRIC1310PRIC13101408 — Enable Write Protection of PRIC1310PRIC1_310[14:08]
  [14] EnblRstToleranceOfPRIC1310PRIC13101308 — Enable Reset Tolerance of PRIC1310PRIC1_310[13:08]
    0=Reset_By_SRST; 1=Reset_By_SRST_And_PSP_Reset
  [n+8] EnblReadGroup{n}OfUSB2PortC (n=0..5) — Enable Read Group #{n} of USB2 Port C
  [7] EnblWrProtOfPRIC1310PRIC13100600 — Enable Write Protection of PRIC1310PRIC1_310[06:00]
  [6] EnblRstToleranceOfPRIC1310PRIC13100500 — Enable Reset Tolerance of PRIC1310PRIC1_310[05:00]
    0=Reset_By_SRST; 1=Reset_By_SRST_And_PSP_Reset
  [n] EnblReadGroup{n}OfUHCI (n=0..5) — Enable Read Group #{n} of UHCI
0x314 PRIC_IO314 reset 0x3F3F3F3F (reset mask 0x0) — Slave Read Group Setting Register \#5
0x318 PRIC_IO318 reset 0x3F3F3F3F (reset mask 0x0) — Slave Read Group Setting Register \#6
0x31C PRIC_IO31C reset 0x3F3F3F3F — Slave Read Group Setting Register \#7
  [31] EnblWrProtOfPRIC131CPRIC131C3024 — Enable Write Protection of PRIC131CPRIC1_31C[30:24]
  [30] EnblRstToleranceOfPRIC131CPRIC131C2924 — Enable Reset Tolerance of PRIC131CPRIC1_31C[29:24]
    0=Reset_By_SRST; 1=Reset_By_SRST_And_PSP_Reset
  [n+24] EnblReadGroup{n}OfADC0 (n=0..5) — Enable Read Group #{n} of ADC 0
0x320 PRIC_IO320 reset 0x3F3F3F3F — Slave Read Group Setting Register \#8
  [23] EnblWrProtOfPRIC1320PRIC13202216 — Enable Write Protection of PRIC1320PRIC1_320[22:16]
  [22] EnblRstToleranceOfPRIC1320PRIC13202116 — Enable Reset Tolerance of PRIC1320PRIC1_320[21:16]
    0=Reset_By_SRST; 1=Reset_By_SRST_And_PSP_Reset
  [n+16] EnblReadGroup{n}OfSCU (n=0..5) — Enable Read Group #{n} of SCU
  [15] EnblWrProtOfPRIC1320PRIC13201408 — Enable Write Protection of PRIC1320PRIC1_320[14:08]
  [14] EnblRstToleranceOfPRIC1320PRIC13201308 — Enable Reset Tolerance of PRIC1320PRIC1_320[13:08]
    0=Reset_By_SRST; 1=Reset_By_SRST_And_PSP_Reset
  [n+8] EnblReadGroup{n}OfJTAG0 (n=0..5) — Enable Read Group #{n} of JTAG0
  [7] EnblWrProtOfPRIC1320PRIC13200600 — Enable Write Protection of PRIC1320PRIC1_320[06:00]
  [6] EnblRstToleranceOfPRIC1320PRIC13200500 — Enable Reset Tolerance of PRIC1320PRIC1_320[05:00]
    0=Reset_By_SRST; 1=Reset_By_SRST_And_PSP_Reset
  [n] EnblReadGroup{n}OfADC1 (n=0..5) — Enable Read Group #{n} of ADC 1
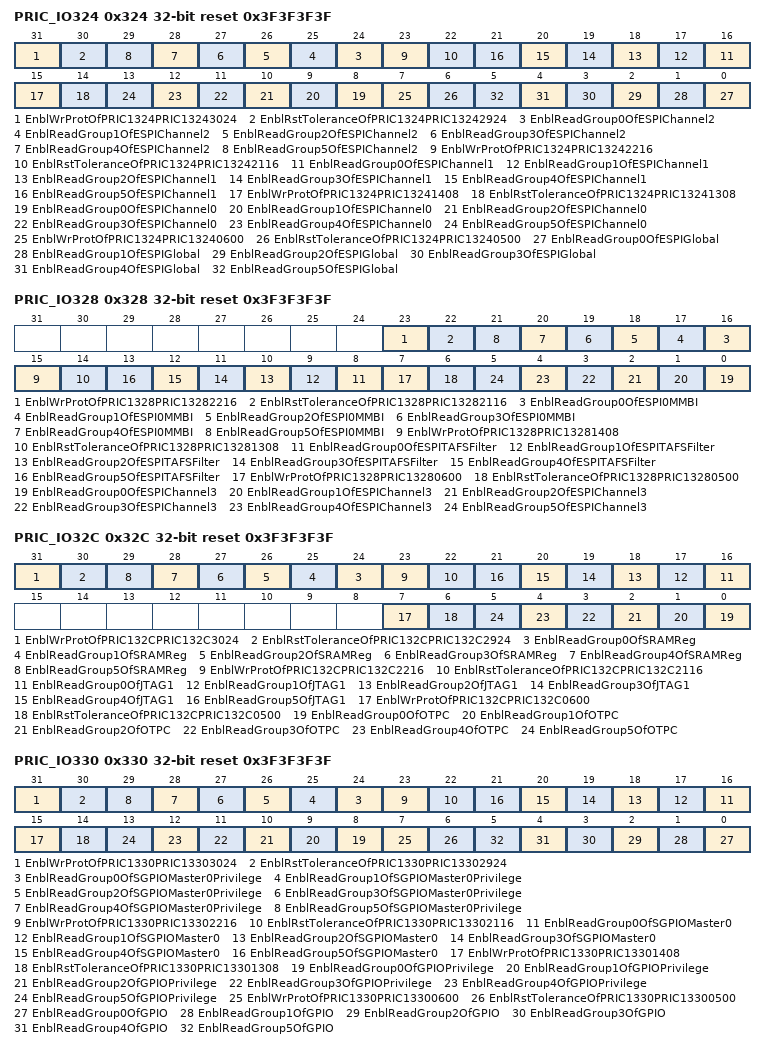
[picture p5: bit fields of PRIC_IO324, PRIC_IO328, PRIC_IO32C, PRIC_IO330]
0x324 PRIC_IO324 reset 0x3F3F3F3F — Slave Read Group Setting Register \#9
  [31] EnblWrProtOfPRIC1324PRIC13243024 — Enable Write Protection of PRIC1324PRIC1_324[30:24]
  [30] EnblRstToleranceOfPRIC1324PRIC13242924 — Enable Reset Tolerance of PRIC1324PRIC1_324[29:24]
    0=Reset_By_SRST; 1=Reset_By_SRST_And_PSP_Reset
  [n+24] EnblReadGroup{n}OfESPIChannel2 (n=0..5) — Enable Read Group #{n} of eSPI Channel 2
  [23] EnblWrProtOfPRIC1324PRIC13242216 — Enable Write Protection of PRIC1324PRIC1_324[22:16]
  [22] EnblRstToleranceOfPRIC1324PRIC13242116 — Enable Reset Tolerance of PRIC1324PRIC1_324[21:16]
    0=Reset_By_SRST; 1=Reset_By_SRST_And_PSP_Reset
  [n+16] EnblReadGroup{n}OfESPIChannel1 (n=0..5) — Enable Read Group #{n} of eSPI Channel 1
  [15] EnblWrProtOfPRIC1324PRIC13241408 — Enable Write Protection of PRIC1324PRIC1_324[14:08]
  [14] EnblRstToleranceOfPRIC1324PRIC13241308 — Enable Reset Tolerance of PRIC1324PRIC1_324[13:08]
    0=Reset_By_SRST; 1=Reset_By_SRST_And_PSP_Reset
  [n+8] EnblReadGroup{n}OfESPIChannel0 (n=0..5) — Enable Read Group #{n} of eSPI Channel 0
  [7] EnblWrProtOfPRIC1324PRIC13240600 — Enable Write Protection of PRIC1324PRIC1_324[06:00]
  [6] EnblRstToleranceOfPRIC1324PRIC13240500 — Enable Reset Tolerance of PRIC1324PRIC1_324[05:00]
    0=Reset_By_SRST; 1=Reset_By_SRST_And_PSP_Reset
  [n] EnblReadGroup{n}OfESPIGlobal (n=0..5) — Enable Read Group #{n} of eSPI Global
0x328 PRIC_IO328 reset 0x3F3F3F3F — Slave Read Group Setting Register \#10
  [23] EnblWrProtOfPRIC1328PRIC13282216 — Enable Write Protection of PRIC1328PRIC1_328[22:16]
  [22] EnblRstToleranceOfPRIC1328PRIC13282116 — Enable Reset Tolerance of PRIC1328PRIC1_328[21:16]
    0=Reset_By_SRST; 1=Reset_By_SRST_And_PSP_Reset
  [n+16] EnblReadGroup{n}OfESPI0MMBI (n=0..5) — Enable Read Group #{n} of eSPI0 MMBI
  [15] EnblWrProtOfPRIC1328PRIC13281408 — Enable Write Protection of PRIC1328PRIC1_328[14:08]
  [14] EnblRstToleranceOfPRIC1328PRIC13281308 — Enable Reset Tolerance of PRIC1328PRIC1_328[13:08]
    0=Reset_By_SRST; 1=Reset_By_SRST_And_PSP_Reset
  [n+8] EnblReadGroup{n}OfESPITAFSFilter (n=0..5) — Enable Read Group #{n} of eSPI TAFS Filter
  [7] EnblWrProtOfPRIC1328PRIC13280600 — Enable Write Protection of PRIC1328PRIC1_328[06:00]
  [6] EnblRstToleranceOfPRIC1328PRIC13280500 — Enable Reset Tolerance of PRIC1328PRIC1_328[05:00]
    0=Reset_By_SRST; 1=Reset_By_SRST_And_PSP_Reset
  [n] EnblReadGroup{n}OfESPIChannel3 (n=0..5) — Enable Read Group #{n} of eSPI Channel 3
0x32C PRIC_IO32C reset 0x3F3F3F3F — Slave Read Group Setting Register \#11
  [31] EnblWrProtOfPRIC132CPRIC132C3024 — Enable Write Protection of PRIC132CPRIC1_32C[30:24]
  [30] EnblRstToleranceOfPRIC132CPRIC132C2924 — Enable Reset Tolerance of PRIC132CPRIC1_32C[29:24]
    0=Reset_By_SRST; 1=Reset_By_SRST_And_PSP_Reset
  [n+24] EnblReadGroup{n}OfSRAMReg (n=0..5) — Enable Read Group #{n} of SRAM Register
  [23] EnblWrProtOfPRIC132CPRIC132C2216 — Enable Write Protection of PRIC132CPRIC1_32C[22:16]
  [22] EnblRstToleranceOfPRIC132CPRIC132C2116 — Enable Reset Tolerance of PRIC132CPRIC1_32C[21:16]
    0=Reset_By_SRST; 1=Reset_By_SRST_And_PSP_Reset
  [n+16] EnblReadGroup{n}OfJTAG1 (n=0..5) — Enable Read Group #{n} of JTAG1
  [7] EnblWrProtOfPRIC132CPRIC132C0600 — Enable Write Protection of PRIC132CPRIC1_32C[06:00]
  [6] EnblRstToleranceOfPRIC132CPRIC132C0500 — Enable Reset Tolerance of PRIC132CPRIC1_32C[05:00]
    0=Reset_By_SRST; 1=Reset_By_SRST_And_PSP_Reset
  [n] EnblReadGroup{n}OfOTPC (n=0..5) — Enable Read Group #{n} of OTPC
0x330 PRIC_IO330 reset 0x3F3F3F3F — Slave Read Group Setting Register \#12
  [31] EnblWrProtOfPRIC1330PRIC13303024 — Enable Write Protection of PRIC1330PRIC1_330[30:24]
  [30] EnblRstToleranceOfPRIC1330PRIC13302924 — Enable Reset Tolerance of PRIC1330PRIC1_330[29:24]
    0=Reset_By_SRST; 1=Reset_By_SRST_And_PSP_Reset
  [n+24] EnblReadGroup{n}OfSGPIOMaster0Privilege (n=0..5) — Enable Read Group #{n} of SGPIO Master 0 Privilege
  [23] EnblWrProtOfPRIC1330PRIC13302216 — Enable Write Protection of PRIC1330PRIC1_330[22:16]
  [22] EnblRstToleranceOfPRIC1330PRIC13302116 — Enable Reset Tolerance of PRIC1330PRIC1_330[21:16]
    0=Reset_By_SRST; 1=Reset_By_SRST_And_PSP_Reset
  [n+16] EnblReadGroup{n}OfSGPIOMaster0 (n=0..5) — Enable Read Group #{n} of SGPIO Master 0
  [15] EnblWrProtOfPRIC1330PRIC13301408 — Enable Write Protection of PRIC1330PRIC1_330[14:08]
  [14] EnblRstToleranceOfPRIC1330PRIC13301308 — Enable Reset Tolerance of PRIC1330PRIC1_330[13:08]
    0=Reset_By_SRST; 1=Reset_By_SRST_And_PSP_Reset
  [n+8] EnblReadGroup{n}OfGPIOPrivilege (n=0..5) — Enable Read Group #{n} of GPIO Privilege
  [7] EnblWrProtOfPRIC1330PRIC13300600 — Enable Write Protection of PRIC1330PRIC1_330[06:00]
  [6] EnblRstToleranceOfPRIC1330PRIC13300500 — Enable Reset Tolerance of PRIC1330PRIC1_330[05:00]
    0=Reset_By_SRST; 1=Reset_By_SRST_And_PSP_Reset
  [n] EnblReadGroup{n}OfGPIO (n=0..5) — Enable Read Group #{n} of GPIO
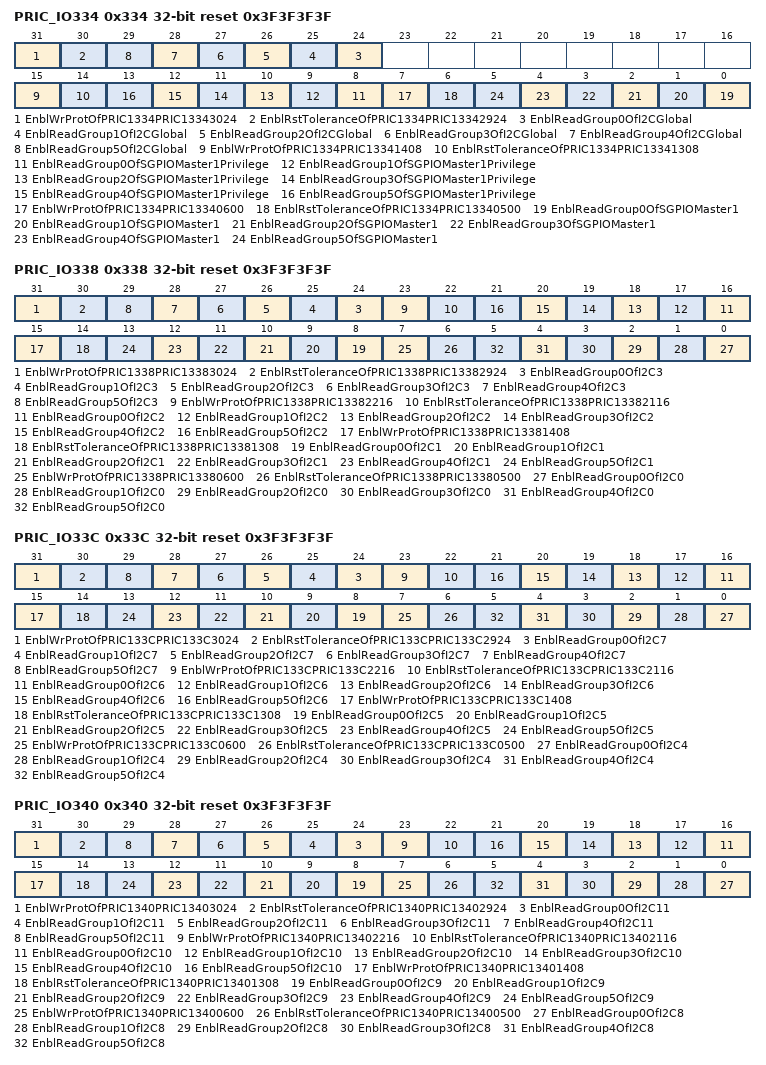
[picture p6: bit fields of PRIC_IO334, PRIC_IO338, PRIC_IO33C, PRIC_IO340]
0x334 PRIC_IO334 reset 0x3F3F3F3F — Slave Read Group Setting Register \#13
  [31] EnblWrProtOfPRIC1334PRIC13343024 — Enable Write Protection of PRIC1334PRIC1_334[30:24]
  [30] EnblRstToleranceOfPRIC1334PRIC13342924 — Enable Reset Tolerance of PRIC1334PRIC1_334[29:24]
    0=Reset_By_SRST; 1=Reset_By_SRST_And_PSP_Reset
  [n+24] EnblReadGroup{n}OfI2CGlobal (n=0..5) — Enable Read Group #{n} of I2C Global
  [15] EnblWrProtOfPRIC1334PRIC13341408 — Enable Write Protection of PRIC1334PRIC1_334[14:08]
  [14] EnblRstToleranceOfPRIC1334PRIC13341308 — Enable Reset Tolerance of PRIC1334PRIC1_334[13:08]
    0=Reset_By_SRST; 1=Reset_By_SRST_And_PSP_Reset
  [n+8] EnblReadGroup{n}OfSGPIOMaster1Privilege (n=0..5) — Enable Read Group #{n} of SGPIO Master 1 Privilege
  [7] EnblWrProtOfPRIC1334PRIC13340600 — Enable Write Protection of PRIC1334PRIC1_334[06:00]
  [6] EnblRstToleranceOfPRIC1334PRIC13340500 — Enable Reset Tolerance of PRIC1334PRIC1_334[05:00]
    0=Reset_By_SRST; 1=Reset_By_SRST_And_PSP_Reset
  [n] EnblReadGroup{n}OfSGPIOMaster1 (n=0..5) — Enable Read Group #{n} of SGPIO Master 1
0x338 PRIC_IO338 reset 0x3F3F3F3F — Slave Read Group Setting Register \#14
  [31] EnblWrProtOfPRIC1338PRIC13383024 — Enable Write Protection of PRIC1338PRIC1_338[30:24]
  [30] EnblRstToleranceOfPRIC1338PRIC13382924 — Enable Reset Tolerance of PRIC1338PRIC1_338[29:24]
    0=Reset_By_SRST; 1=Reset_By_SRST_And_PSP_Reset
  [n+24] EnblReadGroup{n}OfI2C3 (n=0..5) — Enable Read Group #{n} of I2C3
  [23] EnblWrProtOfPRIC1338PRIC13382216 — Enable Write Protection of PRIC1338PRIC1_338[22:16]
  [22] EnblRstToleranceOfPRIC1338PRIC13382116 — Enable Reset Tolerance of PRIC1338PRIC1_338[21:16]
    0=Reset_By_SRST; 1=Reset_By_SRST_And_PSP_Reset
  [n+16] EnblReadGroup{n}OfI2C2 (n=0..5) — Enable Read Group #{n} of I2C2
  [15] EnblWrProtOfPRIC1338PRIC13381408 — Enable Write Protection of PRIC1338PRIC1_338[14:08]
  [14] EnblRstToleranceOfPRIC1338PRIC13381308 — Enable Reset Tolerance of PRIC1338PRIC1_338[13:08]
    0=Reset_By_SRST; 1=Reset_By_SRST_And_PSP_Reset
  [n+8] EnblReadGroup{n}OfI2C1 (n=0..5) — Enable Read Group #{n} of I2C1
  [7] EnblWrProtOfPRIC1338PRIC13380600 — Enable Write Protection of PRIC1338PRIC1_338[06:00]
  [6] EnblRstToleranceOfPRIC1338PRIC13380500 — Enable Reset Tolerance of PRIC1338PRIC1_338[05:00]
    0=Reset_By_SRST; 1=Reset_By_SRST_And_PSP_Reset
  [n] EnblReadGroup{n}OfI2C0 (n=0..5) — Enable Read Group #{n} of I2C0
0x33C PRIC_IO33C reset 0x3F3F3F3F — Slave Read Group Setting Register \#15
  [31] EnblWrProtOfPRIC133CPRIC133C3024 — Enable Write Protection of PRIC133CPRIC1_33C[30:24]
  [30] EnblRstToleranceOfPRIC133CPRIC133C2924 — Enable Reset Tolerance of PRIC133CPRIC1_33C[29:24]
    0=Reset_By_SRST; 1=Reset_By_SRST_And_PSP_Reset
  [n+24] EnblReadGroup{n}OfI2C7 (n=0..5) — Enable Read Group #{n} of I2C7
  [23] EnblWrProtOfPRIC133CPRIC133C2216 — Enable Write Protection of PRIC133CPRIC1_33C[22:16]
  [22] EnblRstToleranceOfPRIC133CPRIC133C2116 — Enable Reset Tolerance of PRIC133CPRIC1_33C[21:16]
    0=Reset_By_SRST; 1=Reset_By_SRST_And_PSP_Reset
  [n+16] EnblReadGroup{n}OfI2C6 (n=0..5) — Enable Read Group #{n} of I2C6
  [15] EnblWrProtOfPRIC133CPRIC133C1408 — Enable Write Protection of PRIC133CPRIC1_33C[14:08]
  [14] EnblRstToleranceOfPRIC133CPRIC133C1308 — Enable Reset Tolerance of PRIC133CPRIC1_33C[13:08]
    0=Reset_By_SRST; 1=Reset_By_SRST_And_PSP_Reset
  [n+8] EnblReadGroup{n}OfI2C5 (n=0..5) — Enable Read Group #{n} of I2C5
  [7] EnblWrProtOfPRIC133CPRIC133C0600 — Enable Write Protection of PRIC133CPRIC1_33C[06:00]
  [6] EnblRstToleranceOfPRIC133CPRIC133C0500 — Enable Reset Tolerance of PRIC133CPRIC1_33C[05:00]
    0=Reset_By_SRST; 1=Reset_By_SRST_And_PSP_Reset
  [n] EnblReadGroup{n}OfI2C4 (n=0..5) — Enable Read Group #{n} of I2C4
0x340 PRIC_IO340 reset 0x3F3F3F3F — Slave Read Group Setting Register \#16
  [31] EnblWrProtOfPRIC1340PRIC13403024 — Enable Write Protection of PRIC1340PRIC1_340[30:24]
  [30] EnblRstToleranceOfPRIC1340PRIC13402924 — Enable Reset Tolerance of PRIC1340PRIC1_340[29:24]
    0=Reset_By_SRST; 1=Reset_By_SRST_And_PSP_Reset
  [n+24] EnblReadGroup{n}OfI2C11 (n=0..5) — Enable Read Group #{n} of I2C11
  [23] EnblWrProtOfPRIC1340PRIC13402216 — Enable Write Protection of PRIC1340PRIC1_340[22:16]
  [22] EnblRstToleranceOfPRIC1340PRIC13402116 — Enable Reset Tolerance of PRIC1340PRIC1_340[21:16]
    0=Reset_By_SRST; 1=Reset_By_SRST_And_PSP_Reset
  [n+16] EnblReadGroup{n}OfI2C10 (n=0..5) — Enable Read Group #{n} of I2C10
  [15] EnblWrProtOfPRIC1340PRIC13401408 — Enable Write Protection of PRIC1340PRIC1_340[14:08]
  [14] EnblRstToleranceOfPRIC1340PRIC13401308 — Enable Reset Tolerance of PRIC1340PRIC1_340[13:08]
    0=Reset_By_SRST; 1=Reset_By_SRST_And_PSP_Reset
  [n+8] EnblReadGroup{n}OfI2C9 (n=0..5) — Enable Read Group #{n} of I2C9
  [7] EnblWrProtOfPRIC1340PRIC13400600 — Enable Write Protection of PRIC1340PRIC1_340[06:00]
  [6] EnblRstToleranceOfPRIC1340PRIC13400500 — Enable Reset Tolerance of PRIC1340PRIC1_340[05:00]
    0=Reset_By_SRST; 1=Reset_By_SRST_And_PSP_Reset
  [n] EnblReadGroup{n}OfI2C8 (n=0..5) — Enable Read Group #{n} of I2C8
